# STM32L432KCU6 register map
File version: 1.0
Registers are 32-bit, access not given, reset 0x0 unless marked. A register's access mark holds for its fields unless they carry their own. Offsets are from the block's base; [hi:lo] are bit positions; {n}, {i} and the like mark numbered series; 'fields as' and 'values as' point back to an identical list.

## SWPMI1
Base 0x40008800
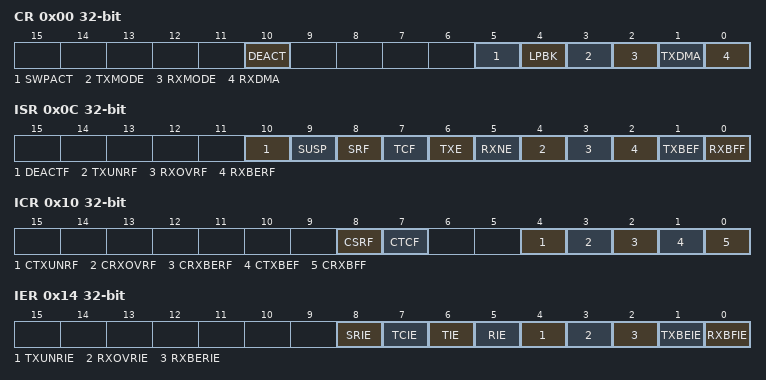
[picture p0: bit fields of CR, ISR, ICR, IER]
0x00 CR
  [10] DEACT, [5] SWPACT, [4] LPBK, [3] TXMODE, [2] RXMODE, [1] TXDMA, [0] RXDMA
0x04 BRR
  [5:0] BR
0x0C ISR
  [10] DEACTF, [9] SUSP, [8] SRF, [7] TCF, [6] TXE, [5] RXNE, [4] TXUNRF, [3] RXOVRF, [2] RXBERF, [1] TXBEF, [0] RXBFF
0x10 ICR
  [8] CSRF, [7] CTCF, [4] CTXUNRF, [3] CRXOVRF, [2] CRXBERF, [1] CTXBEF, [0] CRXBFF
0x14 IER
  [8] SRIE, [7] TCIE, [6] TIE, [5] RIE, [4] TXUNRIE, [3] RXOVRIE, [2] RXBERIE, [1] TXBEIE, [0] RXBFIE
0x18 RFL
  [1:0] RFL_0_1
0x1C TDR
  [31:0] TD
0x20 RDR
  [31:0] RD
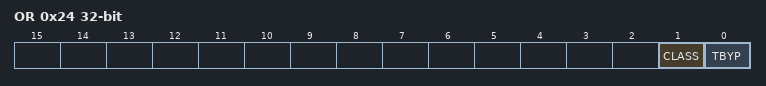
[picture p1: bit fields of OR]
0x24 OR
  [1] CLASS, [0] TBYP

## SYSCFG
Base 0x40010000
0x00 MEMRMP
  [2:0] MEM_MODE
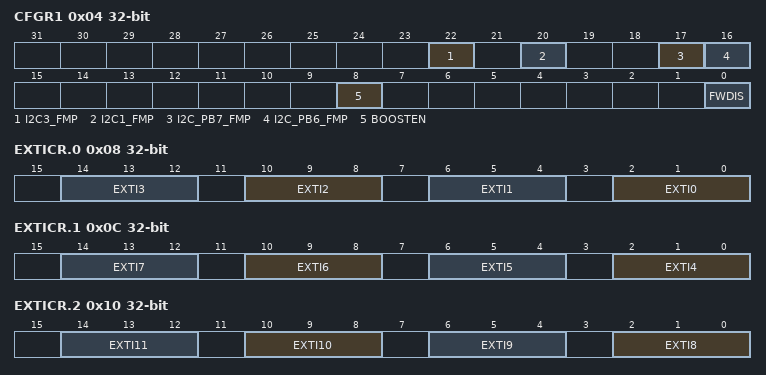
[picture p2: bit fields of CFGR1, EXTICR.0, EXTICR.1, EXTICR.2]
0x04 CFGR1
  [22] I2C3_FMP, [20] I2C1_FMP, [17] I2C_PB7_FMP, [16] I2C_PB6_FMP, [8] BOOSTEN, [0] FWDIS
0x08 EXTICR.0
  [4n+2:4n] EXTI{n} (n=0..3)
0x0C EXTICR.1
  [4n-14:4n-16] EXTI{n} (n=4..7)
0x10 EXTICR.2
  [4n-30:4n-32] EXTI{n} (n=8..11)
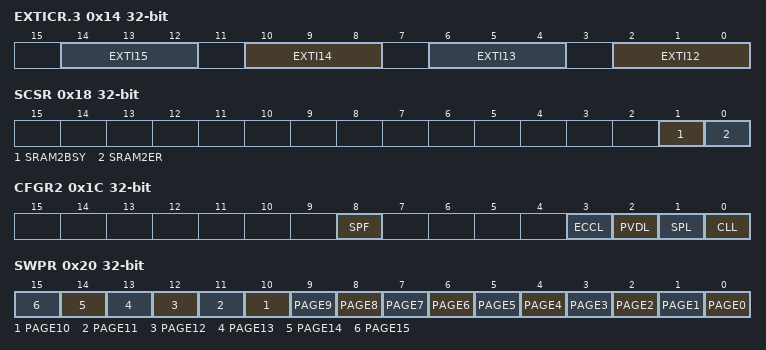
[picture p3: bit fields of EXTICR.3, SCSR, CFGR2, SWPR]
0x14 EXTICR.3
  [4n-46:4n-48] EXTI{n} (n=12..15)
0x18 SCSR
  [1] SRAM2BSY, [0] SRAM2ER
0x1C CFGR2
  [8] SPF, [3] ECCL, [2] PVDL, [1] SPL, [0] CLL
0x20 SWPR
  [n] PAGE{n} (n=0..15)
0x24 SKR
  [7:0] KEY

## COMP1
Base 0x40010200
Same registers: COMP2 0x40010204, COMP12_COMMON 0x40010204
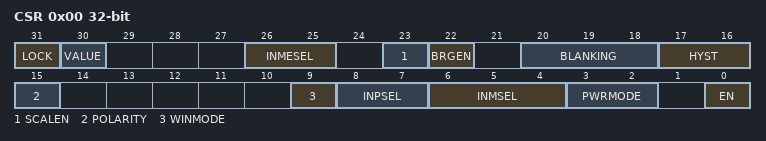
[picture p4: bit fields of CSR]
0x00 CSR
  [31] LOCK, [30] VALUE, [26:25] INMESEL, [23] SCALEN, [22] BRGEN, [20:18] BLANKING, [17:16] HYST, [15] POLARITY, [9] WINMODE, [8:7] INPSEL, [6:4] INMSEL, [3:2] PWRMODE, [0] EN

## EXTI
Base 0x40010400
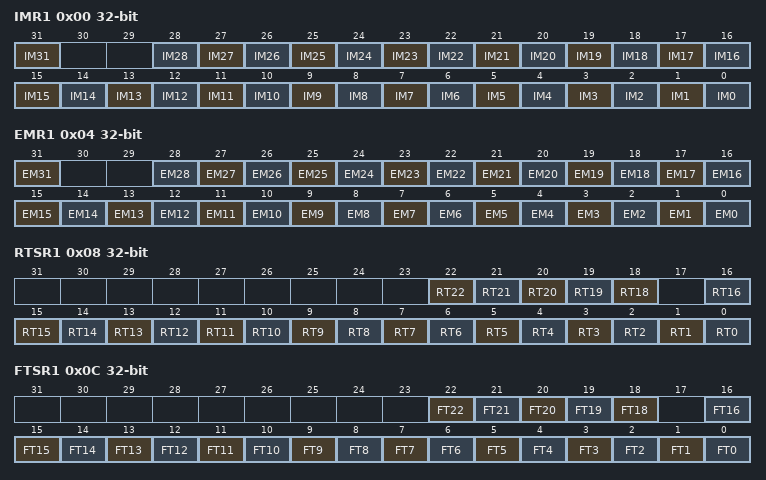
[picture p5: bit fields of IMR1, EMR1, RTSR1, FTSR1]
0x00 IMR1
  [31] IM31, [n] IM{n} (n=0..28)
0x04 EMR1
  [31] EM31, [n] EM{n} (n=0..28)
0x08 RTSR1
  [n] RT{n} (n=18..22), [n] RT{n} (n=0..16)
0x0C FTSR1
  [n] FT{n} (n=18..22), [n] FT{n} (n=0..16)
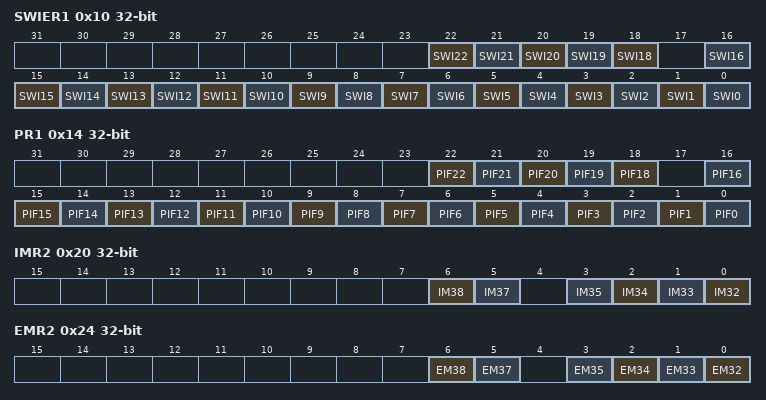
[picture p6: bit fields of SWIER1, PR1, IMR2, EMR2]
0x10 SWIER1
  [n] SWI{n} (n=18..22), [n] SWI{n} (n=0..16)
0x14 PR1
  [n] PIF{n} (n=18..22), [n] PIF{n} (n=0..16)
0x20 IMR2
  [6] IM38, [5] IM37, [n-32] IM{n} (n=32..35)
0x24 EMR2
  [6] EM38, [5] EM37, [n-32] EM{n} (n=32..35)
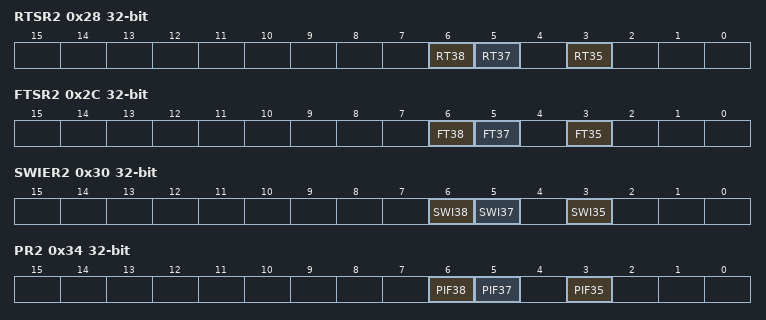
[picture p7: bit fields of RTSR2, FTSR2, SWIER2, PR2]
0x28 RTSR2
  [6] RT38, [5] RT37, [3] RT35
0x2C FTSR2
  [6] FT38, [5] FT37, [3] FT35
0x30 SWIER2
  [6] SWI38, [5] SWI37, [3] SWI35
0x34 PR2
  [6] PIF38, [5] PIF37, [3] PIF35

## FIREWALL
Base 0x40011C00
0x00 CSSA
0x04 CSL
0x08 NVDSSA
0x0C NVDSL
0x10 VDSSA
0x14 VDSL
0x20 CR

## SAI1
Base 0x40015400
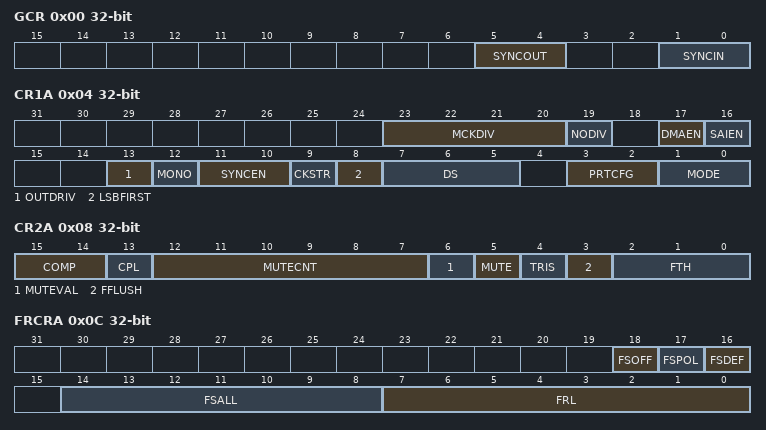
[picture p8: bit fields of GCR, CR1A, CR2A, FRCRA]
0x00 GCR
  [5:4] SYNCOUT, [1:0] SYNCIN
0x04 CR1A
  [23:20] MCKDIV, [19] NODIV, [17] DMAEN, [16] SAIEN, [13] OUTDRIV, [12] MONO, [11:10] SYNCEN, [9] CKSTR, [8] LSBFIRST, [7:5] DS, [3:2] PRTCFG, [1:0] MODE
0x08 CR2A
  [15:14] COMP, [13] CPL, [12:7] MUTECNT, [6] MUTEVAL, [5] MUTE, [4] TRIS, [3] FFLUSH, [2:0] FTH
0x0C FRCRA
  [18] FSOFF, [17] FSPOL, [16] FSDEF, [14:8] FSALL, [7:0] FRL
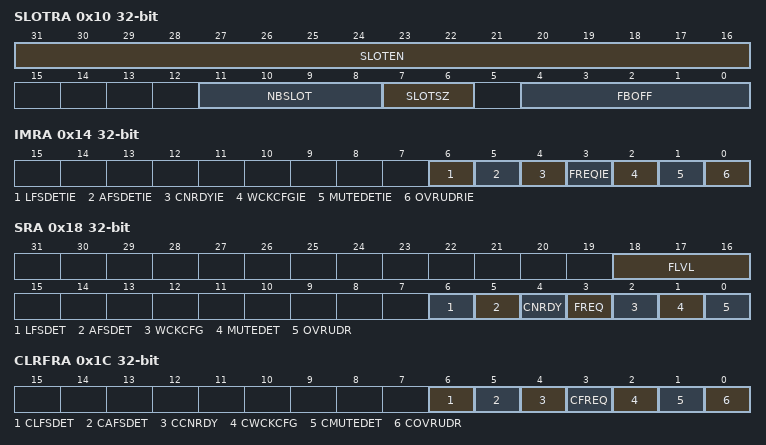
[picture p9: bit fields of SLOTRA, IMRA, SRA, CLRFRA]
0x10 SLOTRA
  [31:16] SLOTEN, [11:8] NBSLOT, [7:6] SLOTSZ, [4:0] FBOFF
0x14 IMRA
  [6] LFSDETIE, [5] AFSDETIE, [4] CNRDYIE, [3] FREQIE, [2] WCKCFGIE, [1] MUTEDETIE, [0] OVRUDRIE
0x18 SRA
  [18:16] FLVL, [6] LFSDET, [5] AFSDET, [4] CNRDY, [3] FREQ, [2] WCKCFG, [1] MUTEDET, [0] OVRUDR
0x1C CLRFRA
  [6] CLFSDET, [5] CAFSDET, [4] CCNRDY, [3] CFREQ, [2] CWCKCFG, [1] CMUTEDET, [0] COVRUDR
0x20 DRA
  [31:0] DATA
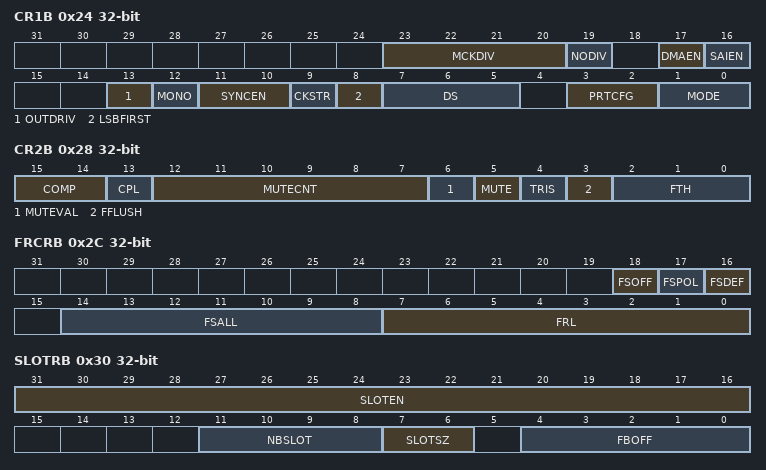
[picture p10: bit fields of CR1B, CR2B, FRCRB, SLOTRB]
0x24 CR1B
  fields as CR1A
0x28 CR2B
  fields as CR2A
0x2C FRCRB
  [18] FSOFF, [17] FSPOL, [16] FSDEF, [14:8] FSALL, [7:0] FRL
0x30 SLOTRB
  [31:16] SLOTEN, [11:8] NBSLOT, [7:6] SLOTSZ, [4:0] FBOFF
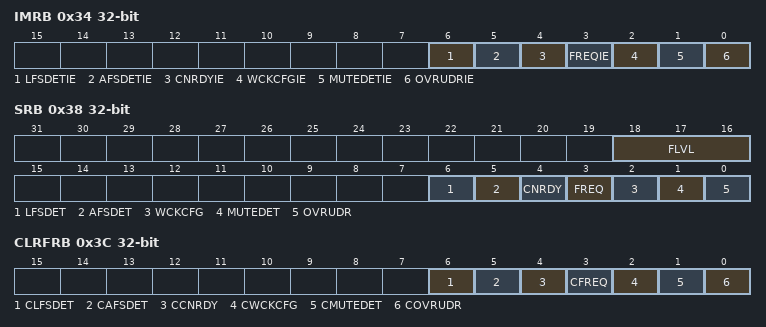
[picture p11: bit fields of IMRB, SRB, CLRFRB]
0x34 IMRB
  fields as IMRA
0x38 SRB
  fields as SRA
0x3C CLRFRB
  fields as CLRFRA
0x40 DRB
  [31:0] DATA

## DMA1
Base 0x40020000
Same registers: DMA2 0x40020400
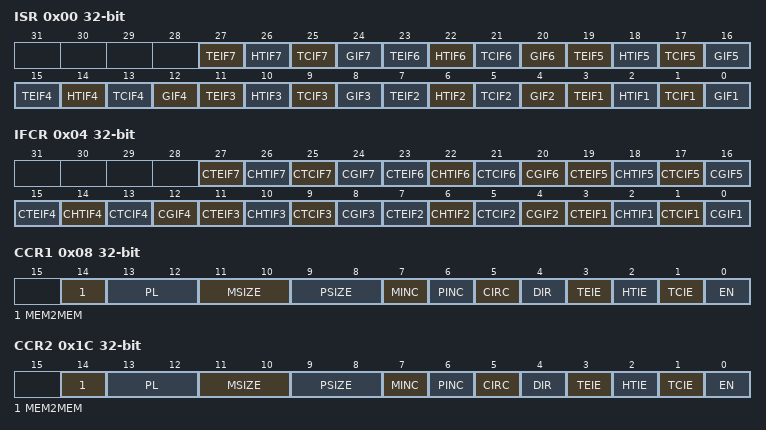
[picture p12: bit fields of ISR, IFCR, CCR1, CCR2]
0x00 ISR
  [4n-1] TEIF{n} (n=1..7), [4n-2] HTIF{n} (n=1..7), [4n-3] TCIF{n} (n=1..7), [4n-4] GIF{n} (n=1..7)
0x04 IFCR
  [4n-1] CTEIF{n} (n=1..7), [4n-2] CHTIF{n} (n=1..7), [4n-3] CTCIF{n} (n=1..7), [4n-4] CGIF{n} (n=1..7)
0x08 CCR1
  [14] MEM2MEM, [13:12] PL, [11:10] MSIZE, [9:8] PSIZE, [7] MINC, [6] PINC, [5] CIRC, [4] DIR, [3] TEIE, [2] HTIE, [1] TCIE, [0] EN
0x0C CNDTR1
  [15:0] NDT
0x10 CPAR1
  [31:0] PA
{0x0+0x14*i} CMAR{i} (i=1..7)
  [31:0] MA
0x1C CCR2
  fields as CCR1
0x20 CNDTR2
  [15:0] NDT
0x24 CPAR2
  [31:0] PA
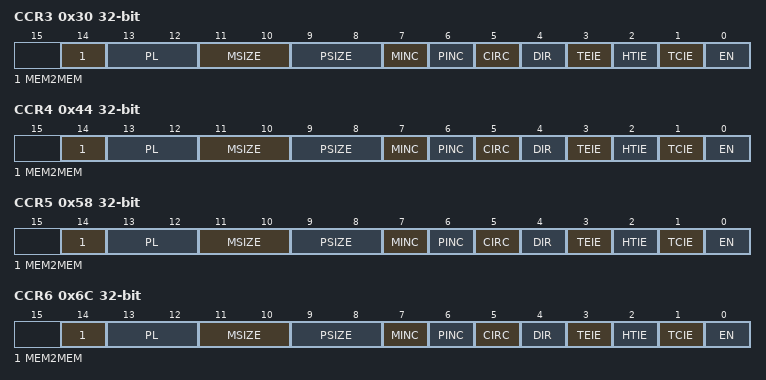
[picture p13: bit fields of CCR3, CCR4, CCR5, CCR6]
0x30 CCR3
  fields as CCR1
0x34 CNDTR3
  [15:0] NDT
0x38 CPAR3
  [31:0] PA
0x44 CCR4
  fields as CCR1
0x48 CNDTR4
  [15:0] NDT
0x4C CPAR4
  [31:0] PA
0x58 CCR5
  fields as CCR1
0x5C CNDTR5
  [15:0] NDT
0x60 CPAR5
  [31:0] PA
0x6C CCR6
  fields as CCR1
0x70 CNDTR6
  [15:0] NDT
0x74 CPAR6
  [31:0] PA
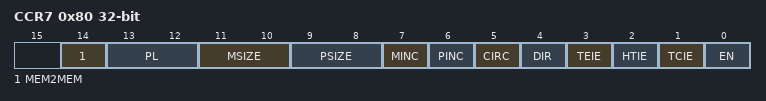
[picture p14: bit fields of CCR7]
0x80 CCR7
  fields as CCR1
0x84 CNDTR7
  [15:0] NDT
0x88 CPAR7
  [31:0] PA
